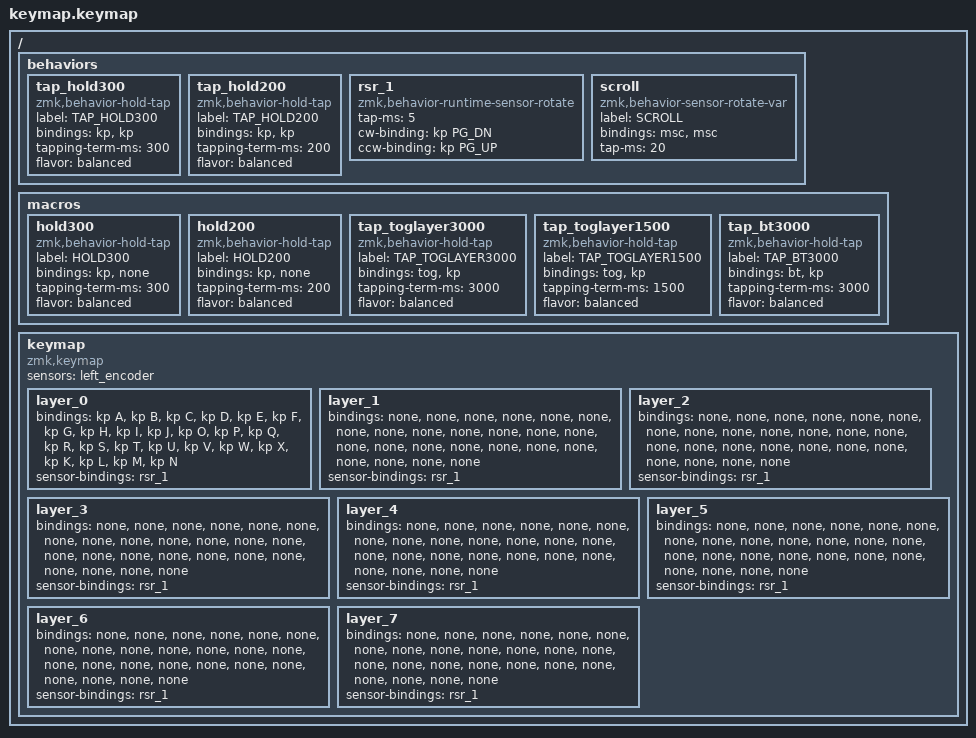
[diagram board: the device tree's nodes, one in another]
#define ZMK_POINTING_DEFAULT_SCRL_VAL 80

#include <behaviors/runtime-sensor-rotate.dtsi>
#include <behaviors.dtsi>
#include <dt-bindings/zmk/bt.h>
#include <dt-bindings/zmk/keys.h>

/ {
    behaviors {
        tap_hold300: tap_hold300 {
            compatible = "zmk,behavior-hold-tap";
            label = "TAP_HOLD300";
            bindings = <&kp>, <&kp>;

            #binding-cells = <2>;
            tapping-term-ms = <300>;
            flavor = "balanced";
        };

        tap_hold200: tap_hold200 {
            compatible = "zmk,behavior-hold-tap";
            label = "TAP_HOLD200";
            bindings = <&kp>, <&kp>;

            #binding-cells = <2>;
            tapping-term-ms = <200>;
            flavor = "balanced";
        };

        rsr_1: rsr_1 {
            compatible = "zmk,behavior-runtime-sensor-rotate";
            #sensor-binding-cells = <0>;
            tap-ms = <5>;
            cw-binding = <&kp PG_DN>;
            ccw-binding = <&kp PG_UP>;
        };

       scroll: scroll {
            compatible = "zmk,behavior-sensor-rotate-var";
            label = "SCROLL";
            #sensor-binding-cells = <2>;
            bindings = <&msc>, <&msc>;

            tap-ms = <20>;
        };
    };

    macros {
        hold300: hold300 {
            compatible = "zmk,behavior-hold-tap";
            label = "HOLD300";
            bindings = <&kp>, <&none>;

            #binding-cells = <2>;
            tapping-term-ms = <300>;
            flavor = "balanced";
        };

        hold200: hold200 {
            compatible = "zmk,behavior-hold-tap";
            label = "HOLD200";
            bindings = <&kp>, <&none>;

            #binding-cells = <2>;
            tapping-term-ms = <200>;
            flavor = "balanced";
        };

        tap_toglayer3000: tap_toglayer3000 {
            compatible = "zmk,behavior-hold-tap";
            label = "TAP_TOGLAYER3000";
            bindings = <&tog>, <&kp>;

            #binding-cells = <2>;
            tapping-term-ms = <3000>;
            flavor = "balanced";
        };

        tap_toglayer1500: tap_toglayer1500 {
            compatible = "zmk,behavior-hold-tap";
            label = "TAP_TOGLAYER1500";
            bindings = <&tog>, <&kp>;

            #binding-cells = <2>;
            tapping-term-ms = <1500>;
            flavor = "balanced";
        };

        tap_bt3000: tap_bt3000 {
            compatible = "zmk,behavior-hold-tap";
            label = "TAP_BT3000";
            bindings = <&bt>, <&kp>;

            #binding-cells = <2>;
            tapping-term-ms = <3000>;
            flavor = "balanced";
        };
    };

    keymap {
        compatible = "zmk,keymap";
        sensors = <&left_encoder>;

        layer_0 {
            bindings = <
&kp A
&kp B
&kp C
&kp D
&kp E
&kp F
&kp G
&kp H
&kp I
&kp J
&kp O
&kp P
&kp Q
&kp R

&kp S
&kp T
&kp U
&kp V
&kp W
&kp X
&kp K
&kp L
&kp M
&kp N
            >;

            sensor-bindings = <&rsr_1>;
        };

        layer_1 {
            bindings = <
&none
&none
&none
&none
&none
&none
&none
&none
&none
&none
&none
&none
&none
&none

&none
&none
&none
&none
&none
&none
&none
&none
&none
&none
            >;

            sensor-bindings = <&rsr_1>;
        };

        layer_2 {
            bindings = <
&none
&none
&none
&none
&none
&none
&none
&none
&none
&none
&none
&none
&none
&none

&none
&none
&none
&none
&none
&none
&none
&none
&none
&none
            >;

            sensor-bindings = <&rsr_1>;
        };

        layer_3 {
            bindings = <
&none
&none
&none
&none
&none
&none
&none
&none
&none
&none
&none
&none
&none
&none

&none
&none
&none
&none
&none
&none
&none
&none
&none
&none
            >;

            sensor-bindings = <&rsr_1>;
        };

        layer_4 {
            bindings = <
&none
&none
&none
&none
&none
&none
&none
&none
&none
&none
&none
&none
&none
&none

&none
&none
&none
&none
&none
&none
&none
&none
&none
&none
            >;

            sensor-bindings = <&rsr_1>;
        };

        layer_5 {
            bindings = <
&none
&none
&none
&none
&none
&none
&none
&none
&none
&none
&none
&none
&none
&none

&none
&none
&none
&none
&none
&none
&none
&none
&none
&none
            >;

            sensor-bindings = <&rsr_1>;
        };

        layer_6 {
            bindings = <
&none
&none
&none
&none
&none
&none
&none
&none
&none
&none
&none
&none
&none
&none

&none
&none
&none
&none
&none
&none
&none
&none
&none
&none
            >;

            sensor-bindings = <&rsr_1>;
        };

        layer_7 {
            bindings = <
&none
&none
&none
&none
&none
&none
&none
&none
&none
&none
&none
&none
&none
&none

&none
&none
&none
&none
&none
&none
&none
&none
&none
&none
            >;

            sensor-bindings = <&rsr_1>;
        };
    };
};
